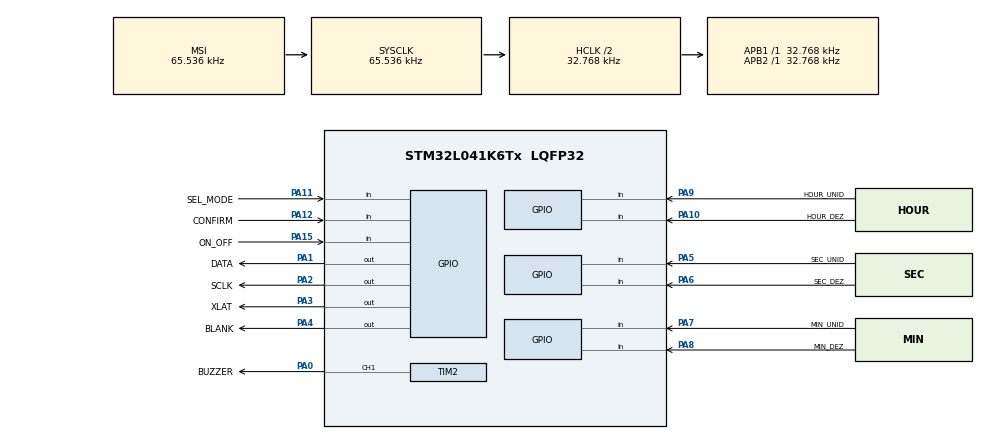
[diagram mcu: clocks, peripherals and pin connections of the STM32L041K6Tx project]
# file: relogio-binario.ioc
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Mcu.Family=STM32L0
Mcu.Name=STM32L041K6Tx
Mcu.Package=LQFP32
NVIC.RTC_IRQn=true\:0\:0\:true\:false\:true\:true\:true\:true
PA0-CK_IN.GPIO_Label=BUZZER
PA0-CK_IN.Signal=S_TIM2_CH1
PA1.GPIO_Label=DATA
PA1.Signal=GPIO_Output
PA10.GPIO_Label=HOUR_DEZ
PA10.Signal=GPIO_Input
PA11.GPIO_Label=SEL_MODE
PA11.Signal=GPIO_Input
PA12.GPIO_Label=CONFIRM
PA12.Signal=GPIO_Input
PA13.Mode=Serial_Wire
PA13.Signal=SYS_SWDIO
PA14.Mode=Serial_Wire
PA14.Signal=SYS_SWCLK
PA15.GPIO_Label=ON_OFF
PA15.GPIO_PuPd=GPIO_PULLDOWN
PA15.Signal=GPIO_Input
PA2.GPIO_Label=SCLK
PA2.Signal=GPIO_Output
PA3.GPIO_Label=XLAT
PA3.Signal=GPIO_Output
PA4.GPIO_Label=BLANK
PA4.PinState=GPIO_PIN_SET
PA4.Signal=GPIO_Output
PA5.GPIO_Label=SEC_UNID
PA5.Signal=GPIO_Input
PA6.GPIO_Label=SEC_DEZ
PA6.Signal=GPIO_Input
PA7.GPIO_Label=MIN_UNID
PA7.Signal=GPIO_Input
PA8.GPIO_Label=MIN_DEZ
PA8.Signal=GPIO_Input
PA9.GPIO_Label=HOUR_UNID
PA9.Signal=GPIO_Input
PC14-OSC32_IN.Mode=LSE-External-Oscillator
PC14-OSC32_IN.Signal=RCC_OSC32_IN
PC15-OSC32_OUT.Mode=LSE-External-Oscillator
PC15-OSC32_OUT.Signal=RCC_OSC32_OUT
ProjectManager.HeapSize=0x200
ProjectManager.StackSize=0x400
ProjectManager.TargetToolchain=STM32CubeIDE
RCC.AHBCLKDivider=RCC_SYSCLK_DIV2
RCC.AHBFreq_Value=32768
RCC.APB1Freq_Value=32768
RCC.APB1TimFreq_Value=32768
RCC.APB2Freq_Value=32768
RCC.APB2TimFreq_Value=32768
RCC.HCLKFreq_Value=32768
RCC.HSE_VALUE=8000000
RCC.HSI16_VALUE=16000000
RCC.HSI_VALUE=16000000
RCC.MSIClockRange=RCC_MSIRANGE_0
RCC.MSI_VALUE=65536
RCC.RTCClockSelection=RCC_RTCCLKSOURCE_LSE
RCC.RTCClockSelectionVirtual=RCC_RTCCLKSOURCE_LSE
RCC.SYSCLKFreq_VALUE=65536
RCC.VCOOutputFreq_Value=48000000
RTC.Alarm-Alarm\ A=RTC_ALARM_A
RTC.WakeUpClock-WakeUp=RTC_WAKEUPCLOCK_CK_SPRE_16BITS
SH.S_TIM2_CH1.0=TIM2_CH1,PWM Generation1 CH1
TIM2.Channel-PWM\ Generation1\ CH1=TIM_CHANNEL_1
TIM2.Period=7
TIM2.Prescaler=7
TIM2.Pulse-PWM\ Generation1\ CH1=3
VP_RTC_VS_RTC_Activate.Mode=RTC_Enabled
VP_RTC_VS_RTC_Alarm_A_Intern.Mode=Alarm A
VP_RTC_VS_RTC_Calendar.Mode=RTC_Calendar
VP_RTC_VS_RTC_WakeUp_intern.Mode=WakeUp
VP_TIM2_VS_ClockSourceINT.Mode=Internal
board=custom

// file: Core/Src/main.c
/* USER CODE BEGIN Header */
/**
  ******************************************************************************
  * @file           : main.c
  * @brief          : Main program body
  ******************************************************************************
  * @attention
  *
  * Copyright (c) 2024 STMicroelectronics.
  * All rights reserved.
  *
  * This software is licensed under terms that can be found in the LICENSE file
  * in the root directory of this software component.
  * If no LICENSE file comes with this software, it is provided AS-IS.
  *
  ******************************************************************************
  */
/* USER CODE END Header */
#include "main.h"

/* USER CODE BEGIN Includes */
#include "app.h"
/* USER CODE END Includes */

RTC_HandleTypeDef hrtc;

TIM_HandleTypeDef htim2;

void SystemClock_Config(void);
static void MX_GPIO_Init(void);
static void MX_RTC_Init(void);
static void MX_TIM2_Init(void);

int main(void)
{

  /* MCU Configuration--------------------------------------------------------*/

  /* Reset of all peripherals, Initializes the Flash interface and the Systick. */
  HAL_Init();

  /* Configure the system clock */
  SystemClock_Config();

  /* Initialize all configured peripherals */
  MX_GPIO_Init();
  MX_RTC_Init();
  MX_TIM2_Init();
  /* USER CODE BEGIN 2 */
  setup(&htim2);
  /* USER CODE END 2 */

  /* Infinite loop */
  /* USER CODE BEGIN WHILE */
  while (1)
  {
	  loop(&htim2);
    /* USER CODE END WHILE */

  }
}

void SystemClock_Config(void)
{
  RCC_OscInitTypeDef RCC_OscInitStruct = {0};
  RCC_ClkInitTypeDef RCC_ClkInitStruct = {0};
  RCC_PeriphCLKInitTypeDef PeriphClkInit = {0};

  /** Configure the main internal regulator output voltage
  */
  __HAL_PWR_VOLTAGESCALING_CONFIG(PWR_REGULATOR_VOLTAGE_SCALE1);

  /** Configure LSE Drive Capability
  */
  HAL_PWR_EnableBkUpAccess();
  __HAL_RCC_LSEDRIVE_CONFIG(RCC_LSEDRIVE_LOW);

  /** Initializes the RCC Oscillators according to the specified parameters
  * in the RCC_OscInitTypeDef structure.
  */
  RCC_OscInitStruct.OscillatorType = RCC_OSCILLATORTYPE_LSE|RCC_OSCILLATORTYPE_MSI;
  RCC_OscInitStruct.LSEState = RCC_LSE_ON;
  RCC_OscInitStruct.MSIState = RCC_MSI_ON;
  RCC_OscInitStruct.MSICalibrationValue = 0;
  RCC_OscInitStruct.MSIClockRange = RCC_MSIRANGE_0;
  RCC_OscInitStruct.PLL.PLLState = RCC_PLL_NONE;
  if (HAL_RCC_OscConfig(&RCC_OscInitStruct) != HAL_OK)
  {
    Error_Handler();
  }

  /** Initializes the CPU, AHB and APB buses clocks
  */
  RCC_ClkInitStruct.ClockType = RCC_CLOCKTYPE_HCLK|RCC_CLOCKTYPE_SYSCLK
                              |RCC_CLOCKTYPE_PCLK1|RCC_CLOCKTYPE_PCLK2;
  RCC_ClkInitStruct.SYSCLKSource = RCC_SYSCLKSOURCE_MSI;
  RCC_ClkInitStruct.AHBCLKDivider = RCC_SYSCLK_DIV2;
  RCC_ClkInitStruct.APB1CLKDivider = RCC_HCLK_DIV1;
  RCC_ClkInitStruct.APB2CLKDivider = RCC_HCLK_DIV1;

  if (HAL_RCC_ClockConfig(&RCC_ClkInitStruct, FLASH_LATENCY_0) != HAL_OK)
  {
    Error_Handler();
  }
  PeriphClkInit.PeriphClockSelection = RCC_PERIPHCLK_RTC;
  PeriphClkInit.RTCClockSelection = RCC_RTCCLKSOURCE_LSE;
  if (HAL_RCCEx_PeriphCLKConfig(&PeriphClkInit) != HAL_OK)
  {
    Error_Handler();
  }
}

static void MX_RTC_Init(void)
{

  RTC_TimeTypeDef sTime = {0};
  RTC_DateTypeDef sDate = {0};
  RTC_AlarmTypeDef sAlarm = {0};

  /** Initialize RTC Only
  */
  hrtc.Instance = RTC;
  hrtc.Init.HourFormat = RTC_HOURFORMAT_24;
  hrtc.Init.AsynchPrediv = 127;
  hrtc.Init.SynchPrediv = 255;
  hrtc.Init.OutPut = RTC_OUTPUT_DISABLE;
  hrtc.Init.OutPutRemap = RTC_OUTPUT_REMAP_NONE;
  hrtc.Init.OutPutPolarity = RTC_OUTPUT_POLARITY_HIGH;
  hrtc.Init.OutPutType = RTC_OUTPUT_TYPE_OPENDRAIN;
  if (HAL_RTC_Init(&hrtc) != HAL_OK)
  {
    Error_Handler();
  }

  /** Initialize RTC and set the Time and Date
  */
  sTime.Hours = 0x0;
  sTime.Minutes = 0x0;
  sTime.Seconds = 0x0;
  sTime.DayLightSaving = RTC_DAYLIGHTSAVING_NONE;
  sTime.StoreOperation = RTC_STOREOPERATION_RESET;
  if (HAL_RTC_SetTime(&hrtc, &sTime, RTC_FORMAT_BCD) != HAL_OK)
  {
    Error_Handler();
  }
  sDate.WeekDay = RTC_WEEKDAY_MONDAY;
  sDate.Month = RTC_MONTH_JANUARY;
  sDate.Date = 0x1;
  sDate.Year = 0x0;

  if (HAL_RTC_SetDate(&hrtc, &sDate, RTC_FORMAT_BCD) != HAL_OK)
  {
    Error_Handler();
  }

  /** Enable the Alarm A
  */
  sAlarm.AlarmTime.Hours = 0x0;
  sAlarm.AlarmTime.Minutes = 0x0;
  sAlarm.AlarmTime.Seconds = 0x0;
  sAlarm.AlarmTime.SubSeconds = 0x0;
  sAlarm.AlarmTime.DayLightSaving = RTC_DAYLIGHTSAVING_NONE;
  sAlarm.AlarmTime.StoreOperation = RTC_STOREOPERATION_RESET;
  sAlarm.AlarmMask = RTC_ALARMMASK_NONE;
  sAlarm.AlarmSubSecondMask = RTC_ALARMSUBSECONDMASK_ALL;
  sAlarm.AlarmDateWeekDaySel = RTC_ALARMDATEWEEKDAYSEL_DATE;
  sAlarm.AlarmDateWeekDay = 0x1;
  sAlarm.Alarm = RTC_ALARM_A;
  if (HAL_RTC_SetAlarm_IT(&hrtc, &sAlarm, RTC_FORMAT_BCD) != HAL_OK)
  {
    Error_Handler();
  }

  /** Enable the WakeUp
  */
  if (HAL_RTCEx_SetWakeUpTimer_IT(&hrtc, 0, RTC_WAKEUPCLOCK_CK_SPRE_16BITS) != HAL_OK)
  {
    Error_Handler();
  }

}

static void MX_TIM2_Init(void)
{

  TIM_ClockConfigTypeDef sClockSourceConfig = {0};
  TIM_MasterConfigTypeDef sMasterConfig = {0};
  TIM_OC_InitTypeDef sConfigOC = {0};

  htim2.Instance = TIM2;
  htim2.Init.Prescaler = 7;
  htim2.Init.CounterMode = TIM_COUNTERMODE_UP;
  htim2.Init.Period = 7;
  htim2.Init.ClockDivision = TIM_CLOCKDIVISION_DIV1;
  htim2.Init.AutoReloadPreload = TIM_AUTORELOAD_PRELOAD_DISABLE;
  if (HAL_TIM_Base_Init(&htim2) != HAL_OK)
  {
    Error_Handler();
  }
  sClockSourceConfig.ClockSource = TIM_CLOCKSOURCE_INTERNAL;
  if (HAL_TIM_ConfigClockSource(&htim2, &sClockSourceConfig) != HAL_OK)
  {
    Error_Handler();
  }
  if (HAL_TIM_PWM_Init(&htim2) != HAL_OK)
  {
    Error_Handler();
  }
  sMasterConfig.MasterOutputTrigger = TIM_TRGO_RESET;
  sMasterConfig.MasterSlaveMode = TIM_MASTERSLAVEMODE_DISABLE;
  if (HAL_TIMEx_MasterConfigSynchronization(&htim2, &sMasterConfig) != HAL_OK)
  {
    Error_Handler();
  }
  sConfigOC.OCMode = TIM_OCMODE_PWM1;
  sConfigOC.Pulse = 3;
  sConfigOC.OCPolarity = TIM_OCPOLARITY_HIGH;
  sConfigOC.OCFastMode = TIM_OCFAST_DISABLE;
  if (HAL_TIM_PWM_ConfigChannel(&htim2, &sConfigOC, TIM_CHANNEL_1) != HAL_OK)
  {
    Error_Handler();
  }
  HAL_TIM_MspPostInit(&htim2);

}

static void MX_GPIO_Init(void)
{
  GPIO_InitTypeDef GPIO_InitStruct = {0};

  /* GPIO Ports Clock Enable */
  __HAL_RCC_GPIOC_CLK_ENABLE();
  __HAL_RCC_GPIOA_CLK_ENABLE();

  /*Configure GPIO pin Output Level */
  HAL_GPIO_WritePin(GPIOA, DATA_Pin|SCLK_Pin|XLAT_Pin, GPIO_PIN_RESET);

  /*Configure GPIO pin Output Level */
  HAL_GPIO_WritePin(BLANK_GPIO_Port, BLANK_Pin, GPIO_PIN_SET);

  /*Configure GPIO pins : DATA_Pin SCLK_Pin XLAT_Pin BLANK_Pin */
  GPIO_InitStruct.Pin = DATA_Pin|SCLK_Pin|XLAT_Pin|BLANK_Pin;
  GPIO_InitStruct.Mode = GPIO_MODE_OUTPUT_PP;
  GPIO_InitStruct.Pull = GPIO_NOPULL;
  GPIO_InitStruct.Speed = GPIO_SPEED_FREQ_LOW;
  HAL_GPIO_Init(GPIOA, &GPIO_InitStruct);

  /*Configure GPIO pins : SEC_UNID_Pin SEC_DEZ_Pin MIN_UNID_Pin MIN_DEZ_Pin
                           HOUR_UNID_Pin HOUR_DEZ_Pin SEL_MODE_Pin CONFIRM_Pin */
  GPIO_InitStruct.Pin = SEC_UNID_Pin|SEC_DEZ_Pin|MIN_UNID_Pin|MIN_DEZ_Pin
                          |HOUR_UNID_Pin|HOUR_DEZ_Pin|SEL_MODE_Pin|CONFIRM_Pin;
  GPIO_InitStruct.Mode = GPIO_MODE_INPUT;
  GPIO_InitStruct.Pull = GPIO_NOPULL;
  HAL_GPIO_Init(GPIOA, &GPIO_InitStruct);

  /*Configure GPIO pin : ON_OFF_Pin */
  GPIO_InitStruct.Pin = ON_OFF_Pin;
  GPIO_InitStruct.Mode = GPIO_MODE_INPUT;
  GPIO_InitStruct.Pull = GPIO_PULLDOWN;
  HAL_GPIO_Init(ON_OFF_GPIO_Port, &GPIO_InitStruct);

}

void Error_Handler(void)
{
  __disable_irq();
  while (1)
  {
  }
}
